# StarFive VisionFive 2 v1.3B register map
File version: 0.1
Registers are 32-bit, read-write, reset 0x0 unless marked. A register's access mark holds for its fields unless they carry their own. Offsets are from the block's base; [hi:lo] are bit positions; {n}, {i} and the like mark numbered series; 'fields as' and 'values as' point back to an identical list.

## clint — From starfive,jh7110-clint, peripheral generator
Base 0x02000000
{0x0+4i} msip_{i} (i=0..4) — MSIP Register for hart {i}
  [0] control
{0x4000+8i} mtimecmp_{i} 64-bit (i=0..4) — MTIMECMP Register for hart {i}
  [63:0] cycles
0xBFF8 mtime 64-bit
  [63:0] cycles

## plic — From starfive,jh7110-plic, peripheral generator
Base 0x0C000000
{0x0+4i} priority_{i} (i=1..136) — PRIORITY Register for interrupt id {i}
  [31:0] priority
{0x1000+4i} pending_{i} (i=0..3) — PENDING Register for interrupt ids {32i+31} to {32i}
  [31:0] pending
0x1010 pending_4 — PENDING Register for interrupt ids 136 to 128
  [31:0] pending
{0x2000+0x80*i} enable_0_{i} (i=0..4) — ENABLE Register for interrupt ids 31 to 0 for hart {i}
  [31:0] enable
{0x2004+0x80*i} enable_1_{i} (i=0..4) — ENABLE Register for interrupt ids 63 to 32 for hart {i}
  [31:0] enable
{0x2008+0x80*i} enable_2_{i} (i=0..4) — ENABLE Register for interrupt ids 95 to 64 for hart {i}
  [31:0] enable
{0x200C+0x80*i} enable_3_{i} (i=0..4) — ENABLE Register for interrupt ids 127 to 96 for hart {i}
  [31:0] enable
{0x2010+0x80*i} enable_4_{i} (i=0..4) — ENABLE Register for interrupt ids 136 to 128 for hart {i}
  [31:0] enable
{0x200000+0x1000*i} threshold_{i} (i=0..4) — PRIORITY THRESHOLD Register for hart {i}
  [31:0] priority
{0x200004+0x1000*i} claimplete_{i} (i=0..4) — CLAIM and COMPLETE Register for hart {i}
  [31:0] claimplete

## trng — From starfive,jh7110-trng, peripheral generator
Base 0x1600C000
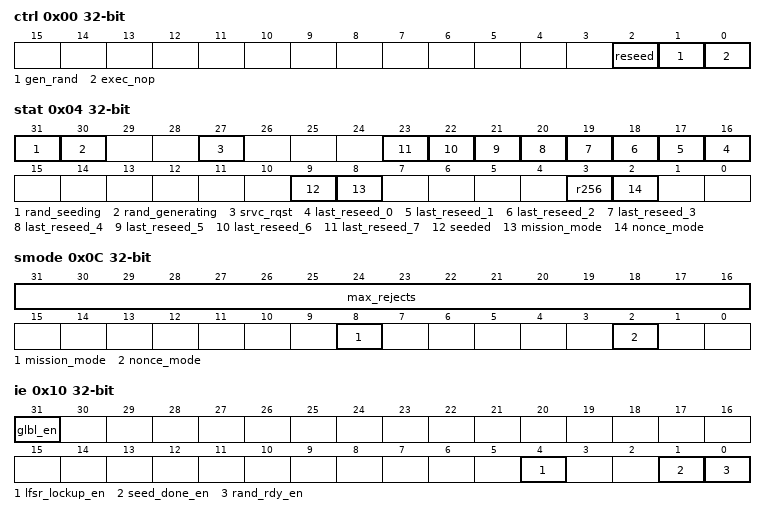
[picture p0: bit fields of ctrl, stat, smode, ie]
0x00 ctrl — TRNG CTRL Register
  [2] reseed — Reseed the TRNG from noise sources
  [1] gen_rand — Generate a random number
  [0] exec_nop — Execute a NOP instruction
0x04 stat — TRNG STAT Register
  [31] rand_seeding ro — TRNG Random Number Seeding Status
  [30] rand_generating ro — TRNG Random Number Generating Status
  [27] srvc_rqst ro — TRNG Service Request
  [n+16] last_reseed_{n} ro (n=0..7) — TRNG Last Reseed {n} status
  [9] seeded ro — TRNG Seeded operating mode
  [8] mission_mode ro — TRNG Mission Mode operating mode
  [3] r256 ro — TRNG 256-bit random number operating mode
  [2] nonce_mode ro — TRNG Nonce operating mode
0x08 mode — TRNG MODE Register
  [3] r256 — 256-bit operation mode: 0 - 128-bit mode, 1 - 256-bit mode
0x0C smode — TRNG SMODE Register
  [31:16] max_rejects — TRNG Maximum Rejects
  [8] mission_mode — Mission operation mode
  [2] nonce_mode — Nonce operation mode
0x10 ie — TRNG Interrupt Enable Register
  [31] glbl_en — Global Enable
  [4] lfsr_lockup_en — LFSR Lockup Enable
  [1] seed_done_en — Seed Done Enable
  [0] rand_rdy_en — RAND Ready Enable
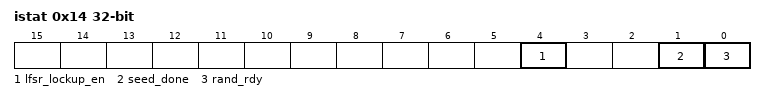
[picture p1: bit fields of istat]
0x14 istat — TRNG Interrupt Status Register
  [4] lfsr_lockup_en ro — LFSR Lockup Enable
  [1] seed_done ro — Seed Done Enable
  [0] rand_rdy ro — RAND Ready Enable
{0x20+4i} rand_{i} (i=0..7) — TRNG RAND {i} Status Register
  [31:0] rand ro — Random number bits
0x60 auto_rqsts — Auto-reseeding after random number requests by host reaches specified counter: 0 - disable counter, other - reload value for internal counter
  [31:0] rqsts — Threshold number of reseed requests for auto-reseed counter
0x64 auto_age — Auto-reseeding after specified timer countdowns to 0: 0 - disable timer, other - reload value for internal timer
  [31:0] age — Countdown value for auto-reseed timer

## aoncrg — From starfive,jh7110-aoncrg, peripheral generator
Base 0x17000000
0x00 clk_osc — Oscillator Clock
  [23:0] clk_divcfg — Clock divider coefficient: Max=4, Default=4, Min=4, Typical=4
0x04 clk_aon_apb — AON APB Function Clock
  [29:24] clk_mux_sel — Clock multiplexing selector: clk_osc_div4, clk_osc
0x08 clk_ahb_gmac5 — AHB GMAC5 Clock
  [31] clk_icg — 1: Clock enable, 0: Clock disable
0x0C clk_axi_gmac5 — AXI GMAC5 Clock
  [31] clk_icg — 1: Clock enable, 0: Clock disable
0x10 clk_gmac0_rmii_rtx — GMAC0 RMII RTX Clock
  [23:0] clk_divcfg — Clock divider coefficient: Max=30, Default=2, Min=2, Typical=2
0x14 clk_gmac5_axi64_tx — GMAC5 AXI64 Clock Transmitter
  [29:24] clk_mux_sel — Clock multiplexing selector: u0_sys_crg_clk_gmac0_gtxclk, clk_gmac0_rmii_rtx
0x18 clk_gmac5_axi64_txi — GMAC5 AXI64 Clock Transmission Inverter
  [30] clk_polarity — 1: Clock inverter, 0: Clock buffer
0x1C clk_gmac5_axi64_rx — GMAC5 AXI64 Clock Receiver
  [23:0] dly_chain_sel — Selector delay chain stage number, totally 32 stages, -50 ps each stage. The register value indicates the delay chain stage number. For example, diy_chain_sel=1 means to delay 1 stage.
0x20 clk_gmac5_axi64_rxi — GMAC5 AXI64 Clock Receiving Inverter
  [30] clk_polarity — 1: Clock inverter, 0: Clock buffer
0x24 clk_optc_apb — OPTC APB Clock
  [31] clk_icg — 1: Clock enable, 0: Clock disable
0x28 clk_rtc_hms_apb — RTC HMS APB Clock
  [31] clk_icg — 1: Clock enable, 0: Clock disable
0x2C clk_rtc_internal — RTC Internal Clock
  [23:0] clk_divcfg — Clock divider coefficient: Max=1022, Default=750, Min=750, Typical=750
0x30 clk_rtc_hms_osc32k — RTC HMS Clock Oscillator 32K
  [29:24] clk_mux_sel — Clock multiplexing selector: clk_rtc, clk_rtc_internal
0x34 clk_rtc_hms_cal — RTC HMS Clock Calculator
  [31] clk_icg — 1: Clock enable, 0: Clock disable
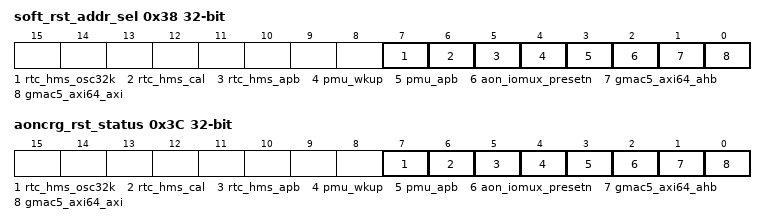
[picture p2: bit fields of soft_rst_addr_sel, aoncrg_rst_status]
0x38 soft_rst_addr_sel — Software RESET Address Selector
  [7] rtc_hms_osc32k — 1: Assert reset, 0: De-assert reset
  [6] rtc_hms_cal — 1: Assert reset, 0: De-assert reset
  [5] rtc_hms_apb — 1: Assert reset, 0: De-assert reset
  [4] pmu_wkup — 1: Assert reset, 0: De-assert reset
  [3] pmu_apb — 1: Assert reset, 0: De-assert reset
  [2] aon_iomux_presetn — 1: Assert reset, 0: De-assert reset
  [1] gmac5_axi64_ahb — 1: Assert reset, 0: De-assert reset
  [0] gmac5_axi64_axi — 1: Assert reset, 0: De-assert reset
0x3C aoncrg_rst_status — AONCRG RESET Status
  fields as soft_rst_addr_sel

## aon_syscon — From starfive,jh7110-aon-syscon, peripheral generator
Base 0x17010000
0x00 aon_syscfg_0 — AON SYSCONSAIF SYSCFG 0
  [31:0] aon_gp_reg
0x04 aon_syscfg_1 — AON SYSCONSAIF SYSCFG 4
  [3:0] u0_boot_ctrl_boot_status ro
0x08 aon_syscfg_2 — AON SYSCONSAIF SYSCFG 8
  [31:0] u0_boot_ctrl_boot_vector_0_31 ro
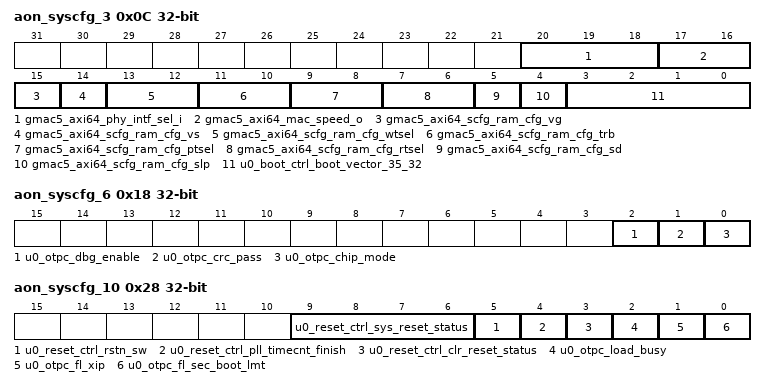
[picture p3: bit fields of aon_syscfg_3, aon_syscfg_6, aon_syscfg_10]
0x0C aon_syscfg_3 — AON SYSCONSAIF SYSCFG 12
  [20:18] gmac5_axi64_phy_intf_sel_i — Active PHY Selected. When you have multiple GMAC PHY interfaces in your configuration, this field indicates the sampled value of the PHY selector during reset de-assertion. Values: 0x0 - GMII or MII, 0x1 - RGMII, 0x2 - SGMII, 0x3 - TBI, 0x4 - RMII, 0x5 - RTBI, 0x6 - SMII, 0x7 - REVMII
  [17:16] gmac5_axi64_mac_speed_o ro
  [15] gmac5_axi64_scfg_ram_cfg_vg — SRAM/ROM configuration. VG: timing setting for debug purpose, default is 1'b1.
  [14] gmac5_axi64_scfg_ram_cfg_vs — SRAM/ROM configuration. VS: timing setting for debug purpose, default is 1'b1.
  [13:12] gmac5_axi64_scfg_ram_cfg_wtsel — SRAM/ROM configuration. WTSEL: timing setting for debug purpose, default is 2'b01.
  [11:10] gmac5_axi64_scfg_ram_cfg_trb — SRAM/ROM configuration. TRB: timing setting for debug purpose, default is 2'b01.
  [9:8] gmac5_axi64_scfg_ram_cfg_ptsel — SRAM/ROM configuration. PTSEL: timing setting for debug purpose, default is 2'b01.
  [7:6] gmac5_axi64_scfg_ram_cfg_rtsel — SRAM/ROM configuration. RTSEL: timing setting for debug purpose, default is 2'b01.
  [5] gmac5_axi64_scfg_ram_cfg_sd — SRAM/ROM configuration. SD: shutdown enable, high active, default is low.
  [4] gmac5_axi64_scfg_ram_cfg_slp — SRAM/ROM configuration. SLP: sleep enable, high active, default is low.
  [3:0] u0_boot_ctrl_boot_vector_35_32 ro
0x10 aon_syscfg_4 — AON SYSCONSAIF SYSCFG 16
  [31:0] gmac5_axi64_ptp_timestamp_o_0_31 ro
0x14 aon_syscfg_5 — AON SYSCONSAIF SYSCFG 20
  [31:0] gmac5_axi64_ptp_timestamp_o_32_63 ro
0x18 aon_syscfg_6 — AON SYSCONSAIF SYSCFG 24
  [2] u0_otpc_dbg_enable ro, [1] u0_otpc_crc_pass ro, [0] u0_otpc_chip_mode ro
0x1C aon_syscfg_7 — AON SYSCONSAIF SYSCFG 28
  [31:0] u0_otpc_fl_func_lock ro
0x20 aon_syscfg_8 — AON SYSCONSAIF SYSCFG 32
  [31:0] u0_otpc_fl_pll0_lock ro
0x24 aon_syscfg_9 — AON SYSCONSAIF SYSCFG 36
  [31:0] u0_otpc_fl_pll1_lock ro
0x28 aon_syscfg_10 — AON SYSCONSAIF SYSCFG 40
  [9:6] u0_reset_ctrl_sys_reset_status ro, [5] u0_reset_ctrl_rstn_sw, [4] u0_reset_ctrl_pll_timecnt_finish ro, [3] u0_reset_ctrl_clr_reset_status, [2] u0_otpc_load_busy ro, [1] u0_otpc_fl_xip ro, [0] u0_otpc_fl_sec_boot_lmt ro
